# Z20K14xM register map
Vendor: Zhixin Semiconductor; Series: Z20K14xM; File version: 0.1.0
CPU: CM4 r0p1, little endian, no MPU, FPU, 4 interrupt priority bits
Registers are 32-bit, read-write, reset 0x0 unless marked. A register's access mark holds for its fields unless they carry their own. Offsets are from the block's base; [hi:lo] are bit positions.

## SCC
Base 0x40064000
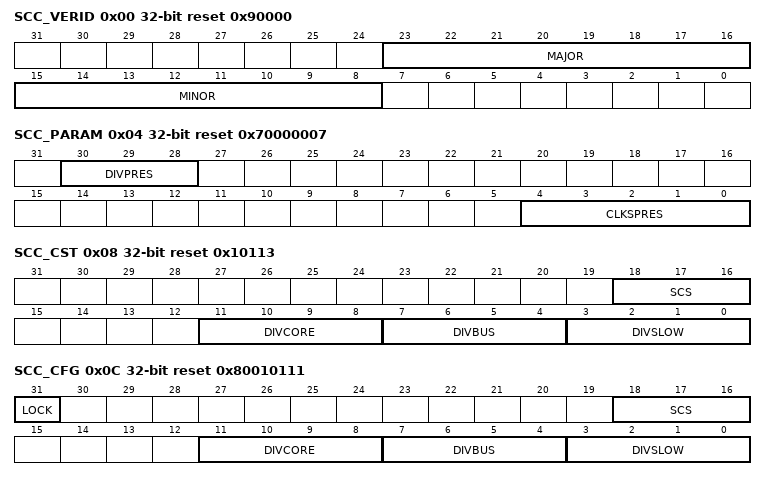
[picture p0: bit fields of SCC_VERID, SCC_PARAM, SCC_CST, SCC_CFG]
0x00 SCC_VERID ro reset 0x90000 — System Clock Control Version Idenfication(SCC_VERID)
  [23:16] MAJOR — Major version
  [15:8] MINOR — Minor version
0x04 SCC_PARAM ro reset 0x70000007 — System Clock Control Parameter(SCC_PARAM)
  [30:28] DIVPRES — Divider Present
  [4:0] CLKSPRES — Clock Source Present
0x08 SCC_CST ro reset 0x10113 — System Clock Control Clock Status Registers(SCC_CST)
  [18:16] SCS — System Clock Source
  [11:8] DIVCORE — Core Clock Divide Ratio
  [7:4] DIVBUS — Bus Clock Divide Ratio
  [3:0] DIVSLOW — Slow Clock Divide Ratio
0x0C SCC_CFG reset 0x80010111 — System Clock Control Clock Configuration Registers(SCC_CFG)
  [31] LOCK — Lock register access
  [18:16] SCS — System Clock Source
  [11:8] DIVCORE — Core Clock Divide Ratio
  [7:4] DIVBUS — Bus Clock Divide Ratio
  [3:0] DIVSLOW — Slow Clock Divide Ratio
0x10 SCC_CLKOUTCFG — System Clock Control Clock Out Configuration Registers(SCC_CLKOUTCFG)
  [19:16] CLKOUTSEL — SCC CLKOUT Configuration
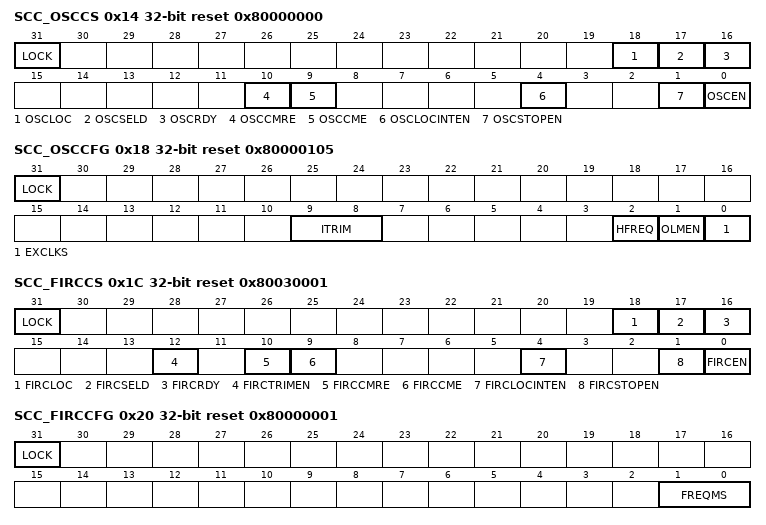
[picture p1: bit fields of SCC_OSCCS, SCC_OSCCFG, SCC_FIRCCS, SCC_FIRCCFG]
0x14 SCC_OSCCS reset 0x80000000 — System Clock Control OSC Control Status Registers(SCC_OSCCS)
  [31] LOCK — Lock register access
  [18] OSCLOC — OSC Loss Of Clock
  [17] OSCSELD — OSC is selected as system clock source
  [16] OSCRDY — OSC is ready for use
  [10] OSCCMRE — OSC Clock Monitor Reset Enabled
  [9] OSCCME — OSC Clock Monitor Enable
  [4] OSCLOCINTEN — OSC loss of clock interrupt enable
  [1] OSCSTOPEN — OSC Stop Mode Enable
  [0] OSCEN — OSC Enable
0x18 SCC_OSCCFG reset 0x80000105 — System Clock Control OSC Configuration Register(SCC_OSCCFG)
  [31] LOCK — Lock register access
  [9:8] ITRIM — Current Trim
  [2] HFREQ — High Frequency Mode
  [1] OLMEN — Open Loop Mode
  [0] EXCLKS — OSC External Clock Select
0x1C SCC_FIRCCS reset 0x80030001 — System Clock Control FIRC Control Status Registers(SCC_FIRCCS)
  [31] LOCK — Lock register access
  [18] FIRCLOC — FIRC Loss Of Clock
  [17] FIRCSELD — FIRC64M is selected as system clock source
  [16] FIRCRDY — FIRC64M is ready for use
  [12] FIRCTRIMEN — Enable FIRC64M trim update
  [10] FIRCCMRE — FIRC Clock Monitor Reset Enabled
  [9] FIRCCME — FIRC Clock Monitor Enable
  [4] FIRCLOCINTEN — FIRC loss of clock interrupt enable
  [1] FIRCSTOPEN — FIRC Stop Mode Enable
  [0] FIRCEN — FIRC Enable
0x20 SCC_FIRCCFG reset 0x80000001 — System Clock Control FIRC Configuration Register(SCC_FIRCCFG)
  [31] LOCK — Lock register access
  [1:0] FREQMS — Frequency Mode Select
0x24 SCC_FIRCTRIM reset 0x1E — System Clock Control FIRC Trim Register(SCC_FIRCTRIM)
  [5:0] TRIM — FRIC64M Trim
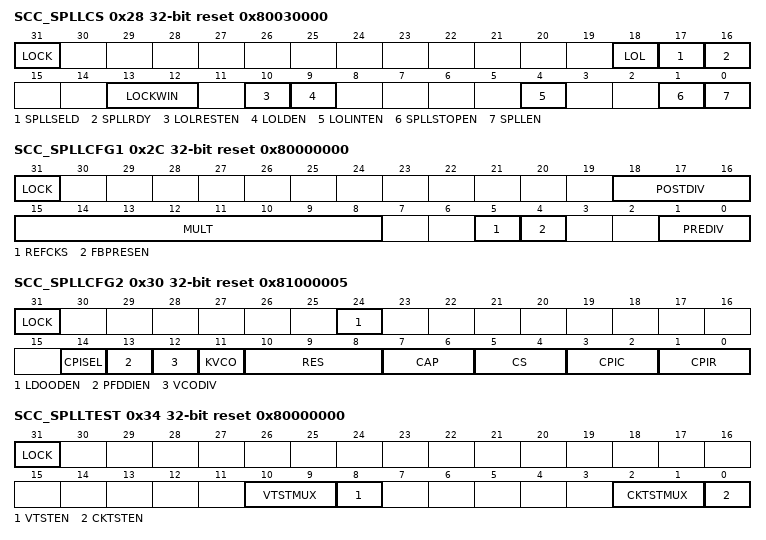
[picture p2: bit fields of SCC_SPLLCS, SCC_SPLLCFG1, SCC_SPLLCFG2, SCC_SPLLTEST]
0x28 SCC_SPLLCS reset 0x80030000 — System Clock Control SPLL Control Status Registers(SCC_SPLLCS)
  [31] LOCK — Lock register access
  [18] LOL — SPLL Loss Of Lock
  [17] SPLLSELD — SPLL is selected as system clock source
  [16] SPLLRDY — SPLL is ready for use
  [13:12] LOCKWIN — SPLL phase lock window
  [10] LOLRESTEN — Loss of lock reset enable
  [9] LOLDEN — Loss of lock detector enable
  [4] LOLINTEN — Loss of lock interrupt request enable
  [1] SPLLSTOPEN — SPLL Stop Mode Enable
  [0] SPLLEN — SPLL Enable
0x2C SCC_SPLLCFG1 reset 0x80000000 — System Clock Control SPLL Configuration Register 1(SCC_SPLLCFG1)
  [31] LOCK — Lock register access
  [18:16] POSTDIV — Post divider
  [15:8] MULT — SPLL multiplier
  [5] REFCKS — Reference clock select
  [4] FBPRESEN — Feedback pre-scaler enable
  [1:0] PREDIV — Pre-divider
0x30 SCC_SPLLCFG2 reset 0x81000005 — System Clock Control SPLL Configuration Register 2(SCC_SPLLCFG2)
  [31] LOCK — Lock register access
  [24] LDOODEN — LDO over drive enable
  [14] CPISEL — pll cp bias option
  [13] PFDDIEN — dither enable
  [12] VCODIV — pll VCO /2 option
  [11] KVCO — kvco gain setting
  [10:8] RES — LPF resistor setting
  [7:6] CAP — LPF cap setting
  [5:4] CS — LPF cap 2nd pole setting
  [3:2] CPIC — charge pump integral path current setting
  [1:0] CPIR — charge pump proportional path current setting
0x34 SCC_SPLLTEST reset 0x80000000 — System Clock Control SPLL Test Register 2(SCC_SPLLTEST)
  [31] LOCK — Lock register access
  [10:9] VTSTMUX — pll voltage test mux slection
  [8] VTSTEN — pll voltage test enable
  [2:1] CKTSTMUX — pll clock test mux slection
  [0] CKTSTEN — pll clock test enable
